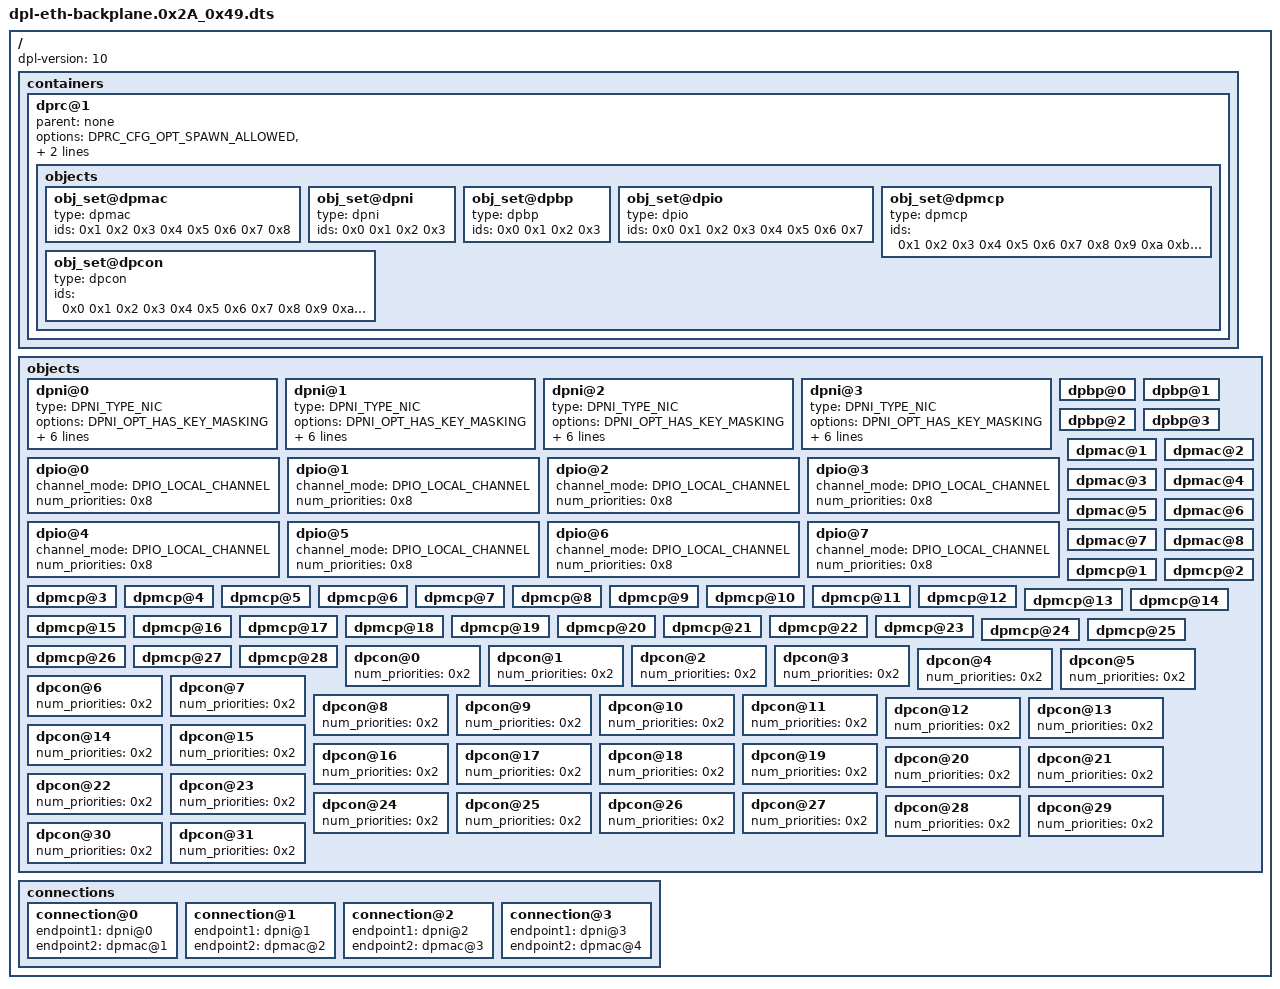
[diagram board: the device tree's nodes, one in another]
/*
 * Copyright 2016 Freescale Semiconductor, Inc.
 * Copyright 2017 NXP
 *
 * Redistribution and use in source and binary forms, with or without
 * modification, are permitted provided that the following conditions are met:
 *   * Redistributions of source code must retain the above copyright
 *     notice, this list of conditions and the following disclaimer.
 *   * Redistributions in binary form must reproduce the above copyright
 *     notice, this list of conditions and the following disclaimer in the
 *     documentation and/or other materials provided with the distribution.
 *   * Neither the name of the above-listed copyright holders nor the
 *     names of any contributors may be used to endorse or promote products
 *     derived from this software without specific prior written permission.
 *
 * THIS SOFTWARE IS PROVIDED BY THE COPYRIGHT HOLDERS AND CONTRIBUTORS "AS IS"
 * AND ANY EXPRESS OR IMPLIED WARRANTIES, INCLUDING, BUT NOT LIMITED TO, THE
 * IMPLIED WARRANTIES OF MERCHANTABILITY AND FITNESS FOR A PARTICULAR PURPOSE
 * ARE DISCLAIMED. IN NO EVENT SHALL THE COPYRIGHT HOLDERS OR CONTRIBUTORS BE
 * LIABLE FOR ANY DIRECT, INDIRECT, INCIDENTAL, SPECIAL, EXEMPLARY, OR
 * CONSEQUENTIAL DAMAGES (INCLUDING, BUT NOT LIMITED TO, PROCUREMENT OF
 * SUBSTITUTE GOODS OR SERVICES; LOSS OF USE, DATA, OR PROFITS; OR BUSINESS
 * INTERRUPTION) HOWEVER CAUSED AND ON ANY THEORY OF LIABILITY, WHETHER IN
 * CONTRACT, STRICT LIABILITY, OR TORT (INCLUDING NEGLIGENCE OR OTHERWISE)
 * ARISING IN ANY WAY OUT OF THE USE OF THIS SOFTWARE, EVEN IF ADVISED OF THE
 * POSSIBILITY OF SUCH DAMAGE.
 */

/*
 * This DPL showcases one Linux configuration for SerDes 0x2A_0x49 with
 * backplane support.
 */

/dts-v1/;
/ {
	dpl-version = <10>;
	/*****************************************************************
	 * Containers
	 *****************************************************************/
	containers {
		dprc@1 {
			parent = "none";
			options = "DPRC_CFG_OPT_SPAWN_ALLOWED" , "DPRC_CFG_OPT_ALLOC_ALLOWED", "DPRC_CFG_OPT_IRQ_CFG_ALLOWED";

			objects {

				obj_set@dpmac {
					type = "dpmac";
					ids = <0x1 0x2 0x3 0x4 0x5 0x6 0x7 0x8>;
				};

				obj_set@dpni {
					type = "dpni";
					ids = <0x0 0x1 0x2 0x3>;
				};

				obj_set@dpbp {
					type = "dpbp";
					ids = <0x0 0x1 0x2 0x3>;
				};

				obj_set@dpio {
					type = "dpio";
					ids = <0x0 0x1 0x2 0x3 0x4 0x5 0x6 0x7>;
				};

				obj_set@dpmcp {
					type = "dpmcp";
					ids = <0x1 0x2 0x3 0x4 0x5 0x6 0x7 0x8 0x9 0xa 0xb 0xc 0xd 0xe 0xf 0x10 0x11 0x12 0x13 0x14 0x15 0x16 0x17 0x18 0x19 0x1a 0x1b 0x1c>;
				};

				obj_set@dpcon {
					type = "dpcon";
					ids = <0x0 0x1 0x2 0x3 0x4 0x5 0x6 0x7 0x8 0x9 0xa 0xb 0xc 0xd 0xe 0xf 0x10 0x11 0x12 0x13 0x14 0x15 0x16 0x17 0x18 0x19 0x1a 0x1b 0x1c 0x1d 0x1e 0x1f>;
				};
			};
		};
	};

	/*****************************************************************
	 * Objects
	 *****************************************************************/
	objects {

		dpni@0 {
			type = "DPNI_TYPE_NIC";
			options = "DPNI_OPT_HAS_KEY_MASKING";
			num_queues = <0x8>;
			num_tcs = <0x1>;
			mac_filter_entries = <0x10>;
			vlan_filter_entries = <0x0>;
			fs_entries = <0x12>;
			qos_entries = <0x0>;
		};

		dpni@1 {
			type = "DPNI_TYPE_NIC";
			options = "DPNI_OPT_HAS_KEY_MASKING";
			num_queues = <0x8>;
			num_tcs = <0x1>;
			mac_filter_entries = <0x10>;
			vlan_filter_entries = <0x0>;
			fs_entries = <0x12>;
			qos_entries = <0x0>;
		};

		dpni@2 {
			type = "DPNI_TYPE_NIC";
			options = "DPNI_OPT_HAS_KEY_MASKING";
			num_queues = <0x8>;
			num_tcs = <0x1>;
			mac_filter_entries = <0x10>;
			vlan_filter_entries = <0x0>;
			fs_entries = <0x12>;
			qos_entries = <0x0>;
		};

		dpni@3 {
			type = "DPNI_TYPE_NIC";
			options = "DPNI_OPT_HAS_KEY_MASKING";
			num_queues = <0x8>;
			num_tcs = <0x1>;
			mac_filter_entries = <0x10>;
			vlan_filter_entries = <0x0>;
			fs_entries = <0x12>;
			qos_entries = <0x0>;
		};

		dpbp@0 {
		};

		dpbp@1 {
		};

		dpbp@2 {
		};

		dpbp@3 {
		};

		dpio@0 {
			channel_mode = "DPIO_LOCAL_CHANNEL";
			num_priorities = <0x8>;
		};

		dpio@1 {
			channel_mode = "DPIO_LOCAL_CHANNEL";
			num_priorities = <0x8>;
		};

		dpio@2 {
			channel_mode = "DPIO_LOCAL_CHANNEL";
			num_priorities = <0x8>;
		};

		dpio@3 {
			channel_mode = "DPIO_LOCAL_CHANNEL";
			num_priorities = <0x8>;
		};

		dpio@4 {
			channel_mode = "DPIO_LOCAL_CHANNEL";
			num_priorities = <0x8>;
		};

		dpio@5 {
			channel_mode = "DPIO_LOCAL_CHANNEL";
			num_priorities = <0x8>;
		};

		dpio@6 {
			channel_mode = "DPIO_LOCAL_CHANNEL";
			num_priorities = <0x8>;
		};

		dpio@7 {
			channel_mode = "DPIO_LOCAL_CHANNEL";
			num_priorities = <0x8>;
		};

		dpmac@1 {
		};

		dpmac@2 {
		};

		dpmac@3 {
		};

		dpmac@4 {
		};

		dpmac@5 {
		};

		dpmac@6 {
		};

		dpmac@7 {
		};

		dpmac@8 {
		};

		dpmcp@1 {
		};

		dpmcp@2 {
		};

		dpmcp@3 {
		};

		dpmcp@4 {
		};

		dpmcp@5 {
		};

		dpmcp@6 {
		};

		dpmcp@7 {
		};

		dpmcp@8 {
		};

		dpmcp@9 {
		};

		dpmcp@10 {
		};

		dpmcp@11 {
		};

		dpmcp@12 {
		};

		dpmcp@13 {
		};

		dpmcp@14 {
		};

		dpmcp@15 {
		};

		dpmcp@16 {
		};

		dpmcp@17 {
		};

		dpmcp@18 {
		};

		dpmcp@19 {
		};

		dpmcp@20 {
		};

		dpmcp@21 {
		};

		dpmcp@22 {
		};

		dpmcp@23 {
		};

		dpmcp@24 {
		};

		dpmcp@25 {
		};

		dpmcp@26 {
		};

		dpmcp@27 {
		};

		dpmcp@28 {
		};

		dpcon@0 {
			num_priorities = <0x2>;
		};

		dpcon@1 {
			num_priorities = <0x2>;
		};

		dpcon@2 {
			num_priorities = <0x2>;
		};

		dpcon@3 {
			num_priorities = <0x2>;
		};

		dpcon@4 {
			num_priorities = <0x2>;
		};

		dpcon@5 {
			num_priorities = <0x2>;
		};

		dpcon@6 {
			num_priorities = <0x2>;
		};

		dpcon@7 {
			num_priorities = <0x2>;
		};

		dpcon@8 {
			num_priorities = <0x2>;
		};

		dpcon@9 {
			num_priorities = <0x2>;
		};

		dpcon@10 {
			num_priorities = <0x2>;
		};

		dpcon@11 {
			num_priorities = <0x2>;
		};

		dpcon@12 {
			num_priorities = <0x2>;
		};

		dpcon@13 {
			num_priorities = <0x2>;
		};

		dpcon@14 {
			num_priorities = <0x2>;
		};

		dpcon@15 {
			num_priorities = <0x2>;
		};

		dpcon@16 {
			num_priorities = <0x2>;
		};

		dpcon@17 {
			num_priorities = <0x2>;
		};

		dpcon@18 {
			num_priorities = <0x2>;
		};

		dpcon@19 {
			num_priorities = <0x2>;
		};

		dpcon@20 {
			num_priorities = <0x2>;
		};

		dpcon@21 {
			num_priorities = <0x2>;
		};

		dpcon@22 {
			num_priorities = <0x2>;
		};

		dpcon@23 {
			num_priorities = <0x2>;
		};

		dpcon@24 {
			num_priorities = <0x2>;
		};

		dpcon@25 {
			num_priorities = <0x2>;
		};

		dpcon@26 {
			num_priorities = <0x2>;
		};

		dpcon@27 {
			num_priorities = <0x2>;
		};

		dpcon@28 {
			num_priorities = <0x2>;
		};

		dpcon@29 {
			num_priorities = <0x2>;
		};

		dpcon@30 {
			num_priorities = <0x2>;
		};

		dpcon@31 {
			num_priorities = <0x2>;
		};
	};

	connections {

		connection@0 {
			endpoint1 = "dpni@0";
			endpoint2 = "dpmac@1";
		};

		connection@1 {
			endpoint1 = "dpni@1";
			endpoint2 = "dpmac@2";
		};

		connection@2 {
			endpoint1 = "dpni@2";
			endpoint2 = "dpmac@3";
		};

		connection@3 {
			endpoint1 = "dpni@3";
			endpoint2 = "dpmac@4";
		};
	};
};
